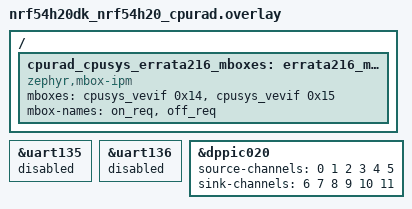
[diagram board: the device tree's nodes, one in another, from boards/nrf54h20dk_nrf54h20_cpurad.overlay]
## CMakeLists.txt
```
cmake_minimum_required(VERSION 3.20.0)

find_package(Zephyr REQUIRED HINTS $ENV{ZEPHYR_BASE})

project(dongle_radio)

target_sources(app PRIVATE
	src/main.c
)

# Reach the shared IPC contract (include/dongle_ipc.h) at the dongle repo root.
target_include_directories(app PRIVATE ${CMAKE_CURRENT_SOURCE_DIR}/../include)
```

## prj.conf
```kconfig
# --- Dongle cpurad (radio core) image ---
# ESB receiver (PRX). Receives ESB mouse packets and forwards each one to
# cpuapp over the ICBMSG IPC link for submission as a USB HID report.

# --- ESB receiver (PRX) ---
CONFIG_ESB=y
CONFIG_ESB_MAX_PAYLOAD_LENGTH=32
# Match the tempo PTX (CONFIG_ESB_FAST_SWITCHING=y): 4 Mbps with the fast radio
# ramp so the auto-ACK turnaround timing lines up on both ends.
CONFIG_ESB_FAST_SWITCHING=y

# HF clock for the radio (nRF54H20 selects CLOCK_CONTROL_NRF2 via the SoC).
CONFIG_CLOCK_CONTROL=y

# --- Inter-core IPC to cpuapp (ICBMSG) via cpuapp_cpurad_ipc ---
CONFIG_IPC_SERVICE=y
CONFIG_IPC_SERVICE_BACKEND_ICBMSG=y
CONFIG_MBOX=y

# --- RTT logging on cpurad ---
CONFIG_LOG=y
CONFIG_LOG_DEFAULT_LEVEL=3
CONFIG_LOG_MODE_DEFERRED=y
CONFIG_LOG_BACKEND_RTT=y
CONFIG_LOG_BACKEND_RTT_MODE_DROP=y
CONFIG_USE_SEGGER_RTT=y
CONFIG_SEGGER_RTT_BUFFER_SIZE_UP=4096

# Route printk() to RTT as well if bring-up code uses it.
CONFIG_CONSOLE=y
CONFIG_RTT_CONSOLE=y
CONFIG_SERIAL=n
CONFIG_UART_CONSOLE=n
CONFIG_PRINTK=y
CONFIG_LOG_PRINTK=y
CONFIG_BOOT_BANNER=n

# Kernel sizing (matches the proven tempo radio image).
CONFIG_MAIN_STACK_SIZE=2048
CONFIG_SYSTEM_WORKQUEUE_STACK_SIZE=2048
CONFIG_ISR_STACK_SIZE=1024
CONFIG_IDLE_STACK_SIZE=512
```

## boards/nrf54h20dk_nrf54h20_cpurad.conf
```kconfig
# Match the NCS esb_prx/esb_ptx cpurad board config: use the GPPI v0 path on
# nRF54H20. Diverging from this caused DPPI setup issues in tempo bringup and
# in the standalone dongle PRX.
CONFIG_NRFX_GPPI_V1=n
```

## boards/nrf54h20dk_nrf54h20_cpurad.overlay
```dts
/*
 * Dongle cpurad overlay — ESB radio (in the cpuapp+cpurad sysbuild).
 *
 * DK base DTS enables uart135/uart136 as cpurad debug consoles. Disable both:
 * we run the radio core headless (prj.conf sets CONFIG_SERIAL=n) and releasing
 * the nodes avoids PERIPHCONF/SPU pin-ownership conflicts with cpuapp.
 */

&uart135 {
	status = "disabled";
};

&uart136 {
	status = "disabled";
};

/ {
	/* HMPAN-216 workaround: cpurad requests power-state changes from cpusys
	 * via VEVIF mboxes. Required by the ESB driver init on nRF54H20.
	 * Channels match the NCS esb samples and the tempo radio app.
	 */
	cpurad_cpusys_errata216_mboxes: errata216_mboxes {
		compatible = "zephyr,mbox-ipm";
		status = "okay";
		mboxes = <&cpusys_vevif 0x14>, <&cpusys_vevif 0x15>;
		mbox-names = "on_req", "off_req";
	};
};

/*
 * Radio<->timer event routing used by the ESB driver on nRF54H20.
 *
 * Unlike the standalone NCS esb_prx sample overlay, gpiote130 is NOT claimed
 * here: the ESB subsystem uses no GPIOTE (only the DK LED/button demo does),
 * and claiming gpiote130 on cpurad in a sysbuild risks a PERIPHCONF conflict.
 * ESB needs only dppic020 + the errata216 mboxes (matches the tempo radio app).
 */
&dppic020 {
	status = "okay";
	source-channels = <0 1 2 3 4 5>;
	sink-channels = <6 7 8 9 10 11>;
};
```

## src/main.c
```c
/*
 * Dongle ESB PRX receiver — radio core (cpurad) image of the dongle sysbuild.
 *
 * Receives Enhanced ShockBurst mouse packets and forwards each one to the
 * application core (cpuapp) over the cpuapp<->cpurad ICBMSG IPC link, where it
 * is turned into a USB HID mouse report. Pairs with an ESB transmitter (PTX)
 * that uses the same addresses and RF channel:
 *
 *   - tempo cpurad PTX    -> RF channel 70 (DONGLE_ESB_CHANNEL = 70)
 *   - NCS esb_ptx sample  -> RF channel 2  (set DONGLE_ESB_CHANNEL = 2)
 *
 * ESB config: DPL (dynamic payload length), 4 Mbps, 16-bit CRC, selective
 * auto-ack on, fast ramp-up. Must match the transmitter byte-for-byte.
 *
 * On-air payload: the canonical 7-byte USB HID mouse report layout
 * (buttons[2] LE + X[2] LE + Y[2] LE + wheel[1]); see include/dongle_ipc.h.
 *
 * The ESB event handler runs in RADIO ISR context, so it only enqueues the
 * payload to a message queue; a dedicated thread drains the queue and performs
 * the (potentially blocking) IPC send.
 */

#include <string.h>
#include <errno.h>

#include <zephyr/kernel.h>
#include <zephyr/device.h>
#include <zephyr/devicetree.h>
#include <zephyr/ipc/ipc_service.h>
#include <zephyr/drivers/clock_control.h>
#include <zephyr/drivers/clock_control/nrf_clock_control.h>
#include <zephyr/logging/log.h>

#include <nrfx.h>
#include <esb.h>
#if defined(CONFIG_CLOCK_CONTROL_NRF2)
#include <hal/nrf_lrcconf.h>
#endif

#include "dongle_ipc.h"

LOG_MODULE_REGISTER(dongle_radio, LOG_LEVEL_INF);

/* RF channel. Must match the transmitter. 70 = the tempo cpurad PTX
 * (TEMPO_ESB_CHANNEL). Use 2 to listen to the NCS esb_ptx sample instead.
 */
#define DONGLE_ESB_CHANNEL 70

/* Shared default addresses (identical in the NCS esb_ptx/esb_prx samples and
 * the tempo cpurad PTX). Must be identical on TX and RX.
 */
static const uint8_t base_addr_0[4]   = {0xE7, 0xE7, 0xE7, 0xE7};
static const uint8_t base_addr_1[4]   = {0xC2, 0xC2, 0xC2, 0xC2};
static const uint8_t addr_prefixes[8] = {
	0xE7, 0xC2, 0xC3, 0xC4, 0xC5, 0xC6, 0xC7, 0xC8,
};

static struct esb_payload rx_payload;
static atomic_t rx_count;
static atomic_t drop_count;

/* ISR -> thread handoff for received mouse reports. */
K_MSGQ_DEFINE(report_msgq, sizeof(struct dongle_ipc_mouse_report), 16, 4);

/* ---- cpuapp IPC link (ICBMSG, single named endpoint) ---- */

static K_SEM_DEFINE(ipc_bound_sem, 0, 1);
static struct ipc_ept radio_ep;

static void radio_ipc_bound(void *priv)
{
	ARG_UNUSED(priv);
	k_sem_give(&ipc_bound_sem);
	LOG_INF("cpuapp IPC endpoint bound");
}

static void radio_ipc_recv(const void *data, size_t len, void *priv)
{
	ARG_UNUSED(data);
	ARG_UNUSED(len);
	ARG_UNUSED(priv);
	/* cpuapp -> cpurad direction is unused in the receiver. */
}

/* Build an IPC mouse report from an ESB payload and enqueue it. Runs in the
 * RADIO ISR via the ESB event handler — non-blocking only.
 */
static void esb_payload_to_msgq(const struct esb_payload *p)
{
	struct dongle_ipc_mouse_report msg = {
		.type = DONGLE_IPC_MOUSE_REPORT,
		.len  = DONGLE_MOUSE_REPORT_SIZE,
	};
	uint8_t n = MIN(p->length, DONGLE_MOUSE_REPORT_SIZE);

	memcpy(msg.report, p->data, n);
	/* Any remaining report[] bytes stay zero from the initializer. */

	if (k_msgq_put(&report_msgq, &msg, K_NO_WAIT) != 0) {
		atomic_inc(&drop_count);
	}
}

static void event_handler(struct esb_evt const *event)
{
	switch (event->evt_id) {
	case ESB_EVENT_TX_SUCCESS:
	case ESB_EVENT_TX_FAILED:
		break;
	case ESB_EVENT_RX_RECEIVED:
		while (esb_read_rx_payload(&rx_payload) == 0) {
			atomic_inc(&rx_count);
			esb_payload_to_msgq(&rx_payload);
		}
		break;
	}
}

/* HF clock start. nRF54H20 uses the CLOCK_CONTROL_NRF2 driver; this is the
 * exact sequence used by the NCS esb_prx sample and the tempo cpurad app.
 */
#if defined(CONFIG_CLOCK_CONTROL_NRF2)
static int clocks_start(void)
{
	int err;
	int res;
	const struct device *radio_clk_dev =
		DEVICE_DT_GET_OR_NULL(DT_CLOCKS_CTLR(DT_NODELABEL(radio)));
	struct onoff_client radio_cli;

	if (radio_clk_dev == NULL) {
		LOG_ERR("radio clock controller not present in DT");
		return -ENODEV;
	}

	/* Keep the radio power domain on to reduce wake latency. */
	nrf_lrcconf_poweron_force_set(NRF_LRCCONF010,
				      NRF_LRCCONF_POWER_DOMAIN_1, true);

	sys_notify_init_spinwait(&radio_cli.notify);

	err = nrf_clock_control_request(radio_clk_dev, NULL, &radio_cli);
	if (err < 0) {
		LOG_ERR("nrf_clock_control_request: %d", err);
		return err;
	}

	do {
		err = sys_notify_fetch_result(&radio_cli.notify, &res);
		if (!err && res) {
			LOG_ERR("HF clock could not be started: %d", res);
			return res;
		}
	} while (err == -EAGAIN);

	/* HMPAN-84 errata: keep the LRCCONF clock running. */
	if (nrf54h_errata_84()) {
		nrf_lrcconf_clock_always_run_force_set(NRF_LRCCONF000, 0, true);
		nrf_lrcconf_task_trigger(NRF_LRCCONF000,
					 NRF_LRCCONF_TASK_CLKSTART_0);
	}

	LOG_INF("HF clock started");
	return 0;
}
#else
#error "This app targets nRF54H20 cpurad (CONFIG_CLOCK_CONTROL_NRF2)."
#endif

static int esb_initialize(void)
{
	int err;
	struct esb_config config = ESB_DEFAULT_CONFIG;

	config.protocol           = ESB_PROTOCOL_ESB_DPL;
	config.mode               = ESB_MODE_PRX;
	config.bitrate            = ESB_BITRATE_4MBPS;
	config.crc                = ESB_CRC_16BIT;
	config.event_handler      = event_handler;
	config.selective_auto_ack = true;
	config.payload_length     = 32;

	if (IS_ENABLED(CONFIG_ESB_FAST_SWITCHING)) {
		config.use_fast_ramp_up = true;
	}

	err = esb_init(&config);
	if (err) {
		LOG_ERR("esb_init: %d", err);
		return err;
	}

	err = esb_set_base_address_0(base_addr_0);
	if (err) {
		return err;
	}

	err = esb_set_base_address_1(base_addr_1);
	if (err) {
		return err;
	}

	err = esb_set_prefixes(addr_prefixes, ARRAY_SIZE(addr_prefixes));
	if (err) {
		return err;
	}

	err = esb_set_rf_channel(DONGLE_ESB_CHANNEL);
	if (err) {
		return err;
	}

	LOG_INF("ESB PRX ready: 4 Mbps DPL, ch=%u, fast-ramp=%d",
		DONGLE_ESB_CHANNEL, IS_ENABLED(CONFIG_ESB_FAST_SWITCHING));
	return 0;
}

/* Drains the RX message queue and forwards each report to cpuapp over IPC.
 * Independent of the ISR so the (potentially blocking) send never runs in
 * RADIO interrupt context.
 */
static void ipc_tx_thread(void *a, void *b, void *c)
{
	ARG_UNUSED(a);
	ARG_UNUSED(b);
	ARG_UNUSED(c);

	/* Wait until cpuapp has bound the endpoint before sending. */
	k_sem_take(&ipc_bound_sem, K_FOREVER);

	struct dongle_ipc_mouse_report msg;

	while (1) {
		k_msgq_get(&report_msgq, &msg, K_FOREVER);

		int ret = ipc_service_send(&radio_ep, &msg, sizeof(msg));

		if (ret < 0) {
			atomic_inc(&drop_count);
		}
	}
}

K_THREAD_DEFINE(ipc_tx_tid, 1024, ipc_tx_thread, NULL, NULL, NULL,
		K_PRIO_PREEMPT(7), 0, 0);

int main(void)
{
	int err;

	LOG_INF("Dongle ESB receiver starting (cpurad)");

	err = clocks_start();
	if (err) {
		LOG_ERR("clocks_start: %d", err);
		return 0;
	}

	err = esb_initialize();
	if (err) {
		LOG_ERR("esb_initialize: %d", err);
		return 0;
	}

	/* Bring up the IPC link to cpuapp. */
	const struct device *ipc_dev =
		DEVICE_DT_GET(DT_NODELABEL(cpuapp_cpurad_ipc));

	if (!device_is_ready(ipc_dev)) {
		LOG_ERR("ICBMSG instance not ready");
		return 0;
	}

	err = ipc_service_open_instance(ipc_dev);
	if (err < 0 && err != -EALREADY) {
		LOG_ERR("ipc_service_open_instance: %d", err);
		return 0;
	}

	static struct ipc_ept_cfg cfg = {
		.name = DONGLE_IPC_EPT_NAME,
		.cb = {
			.bound    = radio_ipc_bound,
			.received = radio_ipc_recv,
		},
	};

	err = ipc_service_register_endpoint(ipc_dev, &radio_ep, &cfg);
	if (err < 0) {
		LOG_ERR("ipc_service_register_endpoint: %d", err);
		return 0;
	}

	err = esb_start_rx();
	if (err) {
		LOG_ERR("esb_start_rx: %d", err);
		return 0;
	}

	LOG_INF("Listening for ESB mouse packets on channel %u...",
		DONGLE_ESB_CHANNEL);

	uint32_t prev = 0;

	while (1) {
		k_sleep(K_SECONDS(1));

		uint32_t now = atomic_get(&rx_count);

		LOG_INF("alive: rx=%u (+%u/s) drops=%u", now, now - prev,
			(unsigned int)atomic_get(&drop_count));
		prev = now;
	}

	return 0;
}
```
